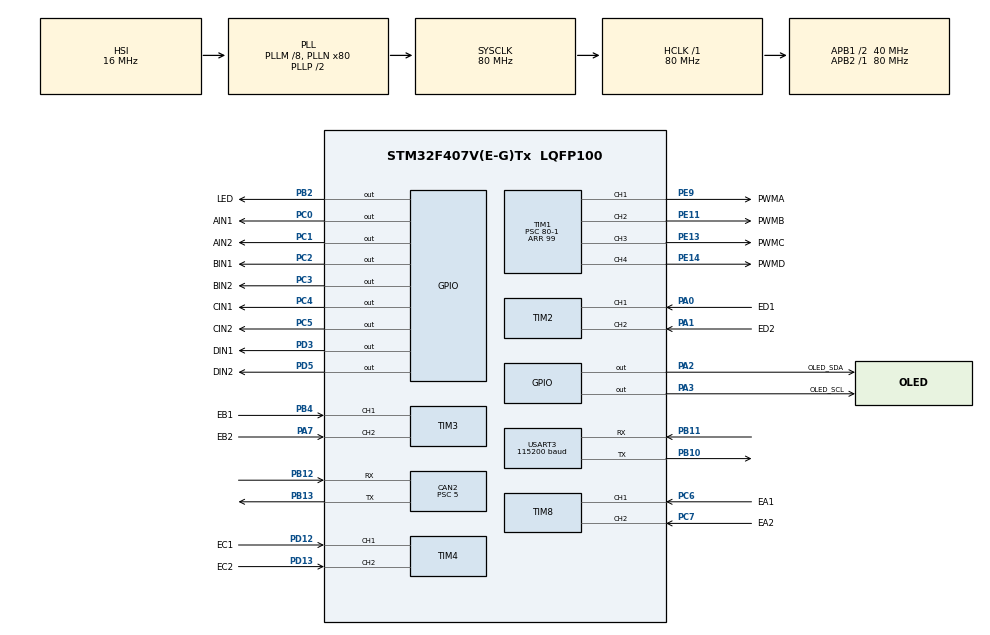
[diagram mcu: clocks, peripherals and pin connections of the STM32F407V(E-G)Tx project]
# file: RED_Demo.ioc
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CAN2.BS1=CAN_BS1_5TQ
CAN2.BS2=CAN_BS2_2TQ
CAN2.CalculateBaudRate=1000000
CAN2.CalculateTimeBit=1000
CAN2.CalculateTimeQuantum=125.0
CAN2.AutoBusOff=ENABLE
CAN2.AutoRetransmission=ENABLE
CAN2.Mode=CAN_MODE_NORMAL
CAN2.Prescaler=5
CAN2.SJW=CAN_SJW_1TQ
Mcu.Family=STM32F4
Mcu.Name=STM32F407V(E-G)Tx
Mcu.Package=LQFP100
NVIC.PriorityGroup=NVIC_PRIORITYGROUP_4
NVIC.TIM2_IRQn=true\:0\:0\:false\:false\:true\:true\:true\:true
NVIC.TIM3_IRQn=true\:0\:0\:false\:false\:true\:true\:true\:true
NVIC.TIM4_IRQn=true\:0\:0\:false\:false\:true\:true\:true\:true
NVIC.TIM5_IRQn=true\:0\:0\:false\:false\:true\:true\:true\:true
NVIC.TIM8_TRG_COM_TIM14_IRQn=true\:0\:0\:false\:false\:true\:true\:true\:true
NVIC.USART3_IRQn=true\:0\:0\:false\:false\:true\:true\:true\:true
PA0-WKUP.GPIO_Label=ED1
PA0-WKUP.Signal=S_TIM2_CH1_ETR
PA1.GPIO_Label=ED2
PA1.Signal=S_TIM2_CH2
PA13.Mode=Serial_Wire
PA13.Signal=SYS_JTMS-SWDIO
PA14.Mode=Serial_Wire
PA14.Signal=SYS_JTCK-SWCLK
PA2.GPIO_Label=OLED_SDA
PA2.GPIO_ModeDefaultOutputPP=GPIO_MODE_OUTPUT_OD
PA2.GPIO_PuPd=GPIO_PULLUP
PA2.Signal=GPIO_Output
PA3.GPIO_Label=OLED_SCL
PA3.GPIO_ModeDefaultOutputPP=GPIO_MODE_OUTPUT_OD
PA3.GPIO_PuPd=GPIO_PULLUP
PA3.Signal=GPIO_Output
PA7.GPIO_Label=EB2
PA7.Signal=S_TIM3_CH2
PB10.Mode=Asynchronous
PB10.Signal=USART3_TX
PB11.Mode=Asynchronous
PB11.Signal=USART3_RX
PB12.Mode=CAN_Activate
PB12.Signal=CAN2_RX
PB13.Mode=CAN_Activate
PB13.Signal=CAN2_TX
PB2.GPIO_Label=LED
PB2.Signal=GPIO_Output
PB4.GPIO_Label=EB1
PB4.Signal=S_TIM3_CH1
PC0.GPIO_Label=AIN1
PC0.Signal=GPIO_Output
PC1.GPIO_Label=AIN2
PC1.Signal=GPIO_Output
PC2.GPIO_Label=BIN1
PC2.Signal=GPIO_Output
PC3.GPIO_Label=BIN2
PC3.Signal=GPIO_Output
PC4.GPIO_Label=CIN1
PC4.Signal=GPIO_Output
PC5.GPIO_Label=CIN2
PC5.Signal=GPIO_Output
PC6.GPIO_Label=EA1
PC6.Signal=S_TIM8_CH1
PC7.GPIO_Label=EA2
PC7.Signal=S_TIM8_CH2
PD12.GPIO_Label=EC1
PD12.Signal=S_TIM4_CH1
PD13.GPIO_Label=EC2
PD13.Signal=S_TIM4_CH2
PD3.GPIO_Label=DIN1
PD3.Signal=GPIO_Output
PD5.GPIO_Label=DIN2
PD5.Signal=GPIO_Output
PE11.GPIO_Label=PWMB
PE11.Signal=S_TIM1_CH2
PE13.GPIO_Label=PWMC
PE13.Signal=S_TIM1_CH3
PE14.GPIO_Label=PWMD
PE14.Signal=S_TIM1_CH4
PE9.GPIO_Label=PWMA
PE9.Signal=S_TIM1_CH1
PH0-OSC_IN.Mode=HSE-External-Oscillator
PH0-OSC_IN.Signal=RCC_OSC_IN
PH1-OSC_OUT.Mode=HSE-External-Oscillator
PH1-OSC_OUT.Signal=RCC_OSC_OUT
ProjectManager.HeapSize=0x200
ProjectManager.StackSize=0x400
ProjectManager.TargetToolchain=MDK-ARM V5.32
RCC.48MHZClocksFreq_Value=40000000
RCC.AHBFreq_Value=80000000
RCC.APB1CLKDivider=RCC_HCLK_DIV2
RCC.APB1Freq_Value=40000000
RCC.APB1TimFreq_Value=80000000
RCC.APB2Freq_Value=80000000
RCC.APB2TimFreq_Value=80000000
RCC.CortexFreq_Value=80000000
RCC.HCLKFreq_Value=80000000
RCC.HSE_VALUE=8000000
RCC.HSI_VALUE=16000000
RCC.LSE_VALUE=32768
RCC.PLLM=8
RCC.PLLN=80
RCC.SYSCLKFreq_VALUE=80000000
RCC.SYSCLKSource=RCC_SYSCLKSOURCE_PLLCLK
RCC.VCOOutputFreq_Value=160000000
SH.S_TIM1_CH1.0=TIM1_CH1,PWM Generation1 CH1
SH.S_TIM1_CH2.0=TIM1_CH2,PWM Generation2 CH2
SH.S_TIM1_CH3.0=TIM1_CH3,PWM Generation3 CH3
SH.S_TIM1_CH4.0=TIM1_CH4,PWM Generation4 CH4
SH.S_TIM2_CH1_ETR.0=TIM2_CH1,Encoder_Interface
SH.S_TIM2_CH2.0=TIM2_CH2,Encoder_Interface
SH.S_TIM3_CH1.0=TIM3_CH1,Encoder_Interface
SH.S_TIM3_CH2.0=TIM3_CH2,Encoder_Interface
SH.S_TIM4_CH1.0=TIM4_CH1,Encoder_Interface
SH.S_TIM4_CH2.0=TIM4_CH2,Encoder_Interface
SH.S_TIM8_CH1.0=TIM8_CH1,Encoder_Interface
SH.S_TIM8_CH2.0=TIM8_CH2,Encoder_Interface
TIM1.Channel-PWM\ Generation1\ CH1=TIM_CHANNEL_1
TIM1.Channel-PWM\ Generation2\ CH2=TIM_CHANNEL_2
TIM1.Channel-PWM\ Generation3\ CH3=TIM_CHANNEL_3
TIM1.Channel-PWM\ Generation4\ CH4=TIM_CHANNEL_4
TIM1.Period=99
TIM1.Prescaler=80-1
TIM1.Pulse-PWM\ Generation1\ CH1=0
TIM1.Pulse-PWM\ Generation2\ CH2=0
TIM1.Pulse-PWM\ Generation3\ CH3=0
TIM1.Pulse-PWM\ Generation4\ CH4=0
TIM2.EncoderMode=TIM_ENCODERMODE_TI12
TIM3.EncoderMode=TIM_ENCODERMODE_TI12
TIM4.EncoderMode=TIM_ENCODERMODE_TI12
TIM5.Period=10000-1
TIM5.Prescaler=80-1
TIM8.EncoderMode=TIM_ENCODERMODE_TI12
USART3.BaudRate=115200
USART3.VirtualMode=VM_ASYNC
VP_TIM5_VS_ClockSourceINT.Mode=Internal
board=custom
PB10.GPIO_PuPd=GPIO_PULLUP
PB11.GPIO_PuPd=GPIO_PULLUP

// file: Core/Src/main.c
/* USER CODE BEGIN Header */
/**
  ******************************************************************************
  * @file           : main.c
  * @brief          : Main program body
  ******************************************************************************
  * @attention
  *
  * Copyright (c) 2026 STMicroelectronics.
  * All rights reserved.
  *
  * This software is licensed under terms that can be found in the LICENSE file
  * in the root directory of this software component.
  * If no LICENSE file comes with this software, it is provided AS-IS.
  *
  ******************************************************************************
  */
#include "headfile.h"
/* USER CODE END Header */

/* USER CODE BEGIN Includes */
#include "can.h"
#include "can_test.h"

/* USER CODE END Includes */

void SystemClock_Config(void);

int main(void)
{

  /* MCU Configuration--------------------------------------------------------*/

  /* Reset of all peripherals, Initializes the Flash interface and the Systick. */
  /* 启动 HAL 和系统毫秒计数，后续动作/超时都使用毫秒差计时。 */
  HAL_Init();

  /* Configure the system clock */
  SystemClock_Config();

  /* USER CODE BEGIN SysInit */
  MX_GPIO_Init();
  OLED_PowerOn(); /* GPIO 就绪后先亮屏显示启动信息。 */

  /* USER CODE END SysInit */

  /* Initialize all configured peripherals */
  MX_TIM1_Init();
  MX_TIM2_Init();
  MX_TIM3_Init();
  MX_TIM4_Init();
  MX_TIM8_Init();
  MX_TIM5_Init();
  MX_CAN2_Init();
  MX_USART3_UART_Init();
  /* USER CODE BEGIN 2 */
	Init();
  CAN_Test_Init(); /* 开启正常 CAN2，接收底盘状态和激光距离。 */
  /* USER CODE END 2 */

  /* Infinite loop */
  /* USER CODE BEGIN WHILE */
  while (1)
  {
        CAN_Test_Task(); /* 先收底盘应答，供下面的肘击条件判断使用。 */
		Vision_UART_Task(); /* 解析最新视觉结果，推进作业判断和电机动作。 */
    CAN_Test_Task(); /* 处理新作业请求，及时发送停车/作业/放行状态。 */
		OLED_Display(); /* 内部每 100 ms 更新车辆、动作和四路激光信息。 */
		LED_Blink(500); /* 指示灯每 500 ms 翻转一次。 */
    /* USER CODE END WHILE */

    /* USER CODE BEGIN 3 */
    UART_SendStatus(); /* 每 500 ms 发送一行串口诊断，UART 忙时跳过。 */
  }
  /* USER CODE END 3 */
}

void SystemClock_Config(void)
{
  RCC_OscInitTypeDef RCC_OscInitStruct = {0};
  RCC_ClkInitTypeDef RCC_ClkInitStruct = {0};

  /** Configure the main internal regulator output voltage
  */
  __HAL_RCC_PWR_CLK_ENABLE();
  __HAL_PWR_VOLTAGESCALING_CONFIG(PWR_REGULATOR_VOLTAGE_SCALE1);

  /** Initializes the RCC Oscillators according to the specified parameters
  * in the RCC_OscInitTypeDef structure.
  */
  RCC_OscInitStruct.OscillatorType = RCC_OSCILLATORTYPE_HSI;
  RCC_OscInitStruct.HSIState = RCC_HSI_ON;
  RCC_OscInitStruct.HSICalibrationValue = RCC_HSICALIBRATION_DEFAULT;
  RCC_OscInitStruct.PLL.PLLState = RCC_PLL_ON;
  RCC_OscInitStruct.PLL.PLLSource = RCC_PLLSOURCE_HSI;
  RCC_OscInitStruct.PLL.PLLM = 8;
  RCC_OscInitStruct.PLL.PLLN = 80;
  RCC_OscInitStruct.PLL.PLLP = RCC_PLLP_DIV2;
  RCC_OscInitStruct.PLL.PLLQ = 4;
  if (HAL_RCC_OscConfig(&RCC_OscInitStruct) != HAL_OK)
  {
    Error_Handler();
  }

  /** Initializes the CPU, AHB and APB buses clocks
  */
  RCC_ClkInitStruct.ClockType = RCC_CLOCKTYPE_HCLK|RCC_CLOCKTYPE_SYSCLK
                              |RCC_CLOCKTYPE_PCLK1|RCC_CLOCKTYPE_PCLK2;
  RCC_ClkInitStruct.SYSCLKSource = RCC_SYSCLKSOURCE_PLLCLK;
  RCC_ClkInitStruct.AHBCLKDivider = RCC_SYSCLK_DIV1;
  RCC_ClkInitStruct.APB1CLKDivider = RCC_HCLK_DIV2;
  RCC_ClkInitStruct.APB2CLKDivider = RCC_HCLK_DIV1;

  if (HAL_RCC_ClockConfig(&RCC_ClkInitStruct, FLASH_LATENCY_2) != HAL_OK)
  {
    Error_Handler();
  }
}

void Error_Handler(void)
{
  __disable_irq();
  while (1)
  {
  }
}
